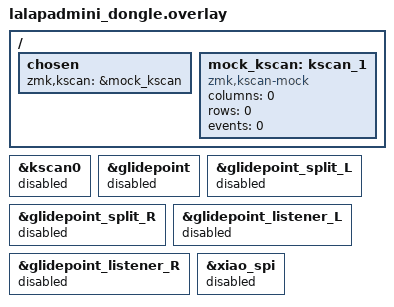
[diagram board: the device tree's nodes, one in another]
#include "lalapadmini.dtsi"

/ {
    chosen {
        zmk,kscan = &mock_kscan;
        /delete-property/ zmk,physical-layout;
    };

    mock_kscan: kscan_1 {
        compatible = "zmk,kscan-mock";
        columns = <0>;
        rows = <0>;
        events = <0>;
    };
};

// Disable the original kscan0 which lacks col-gpios
&kscan0 {
    status = "disabled";
};

// Disable all glidepoint components for dongle mode
&glidepoint {
    status = "disabled";
};

&glidepoint_split_L {
    status = "disabled";
};

&glidepoint_split_R {
    status = "disabled";
};

&glidepoint_listener_L {
    status = "disabled";
};

&glidepoint_listener_R {
    status = "disabled";
};

// Disable SPI interface used by glidepoint
&xiao_spi {
    status = "disabled";
};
